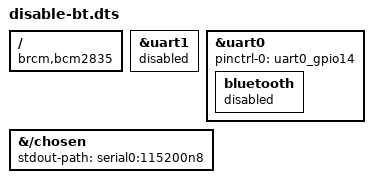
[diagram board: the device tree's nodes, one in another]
/dts-v1/;
/plugin/;

/* Disable Bluetooth and restore UART0/ttyS0 over GPIOs 14 & 15. */

/ {
	compatible = "brcm,bcm2835";
};

&uart1 {
	status = "disabled";
};

&uart0 {
	pinctrl-0 = <&uart0_gpio14>;

	bluetooth {
		status = "disabled";
	};
};

&{/chosen} {
	stdout-path = "serial0:115200n8";
};
